# QN9090 register map
Vendor: nxp.com; File version: 1.0
CPU: CM4 r0p1, little endian, MPU, no FPU, VTOR, 3 interrupt priority bits
Registers are 32-bit, read-write, reset 0x0 unless marked. A register's access mark holds for its fields unless they carry their own. Offsets are from the block's base; [hi:lo] are bit positions; {n}, {i} and the like mark numbered series.

## GPIO — This is the description of component gpio It is General Purpose I/O with APB bus interface. More details will follow.
Base 0x40080000
{0x0+i} B[{i}] (i=0..21) 8-bit — Byte pin registers. Read 0: pin PIOn is LOW. Read 0xFF: pin PIOn is HIGH. Only 0 or 0xFF can be read. Write 0: clear output bit. Write any value 0x01 to 0xFF: set output bit. Reset values reflects the state of pin given by the relevant bit of PIN reset value
  [7:0] B
{0x1000+4i} W[{i}] (i=0..21) — Word pin registers Read 0: pin PIOn is LOW. Read 0xFFFFFFFF: pin PIOn is HIGH. Only 0 or 0xFFFF FFFF can be read. Write 0: clear output bit. Write any value 0x00000001 to 0xFFFFFFFF: set output bit. Reset values reflects the state of pin given by the relevant bit of PIN reset value
  [31:0] W
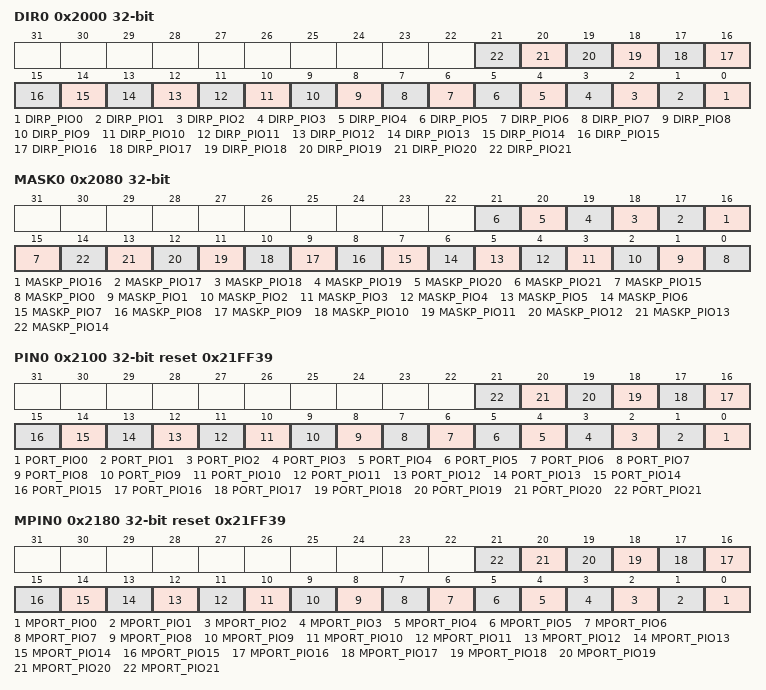
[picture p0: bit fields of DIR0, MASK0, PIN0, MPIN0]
0x2000 DIR0 — Direction register
  [n] DIRP_PIO{n} (n=0..21) — Selects pin direction for pin PIO{n} . 0 = input. 1 = output.
0x2080 MASK0 — Mask register
  [n] MASKP_PIO{n} (n=16..21) — Controls if PIO{n} is active in MPIN register. 0 = Mask bit is clear, the PIO will be active. 1 = Mask bit is set, the PIO will not be active.
  [15] MASKP_PIO15 — Controls if PIO150 is active in MPIN register. 0 = Mask bit is clear, the PIO will be active. 1 = Mask bit is set, the PIO will not be active.
  [n] MASKP_PIO{n} (n=0..14) — Controls if PIO{n} is active in MPIN register. 0 = Mask bit is clear, the PIO will be active. 1 = Mask bit is set, the PIO will not be active.
0x2100 PIN0 reset 0x21FF39 — Pin register
  [n] PORT_PIO{n} (n=0..21) — Reads pin states or loads output bits. 0 = Read: pin is low; write: clear output bit. 1 = Read: pin is high; write: set output bit.
0x2180 MPIN0 reset 0x21FF39 — Masked Pin register
  [n] MPORT_PIO{n} (n=0..21) — Masked pin register. 0 = Read: pin is LOW and/or the corresponding bit in the MASK register is 1; write: clear output bit if the corresponding bit in the MASK register is 0. 1 = Read: pin is HIGH and the corresponding bit in the MASK register is 0; write: set output bit if the corresponding bit in the MASK register is 0.
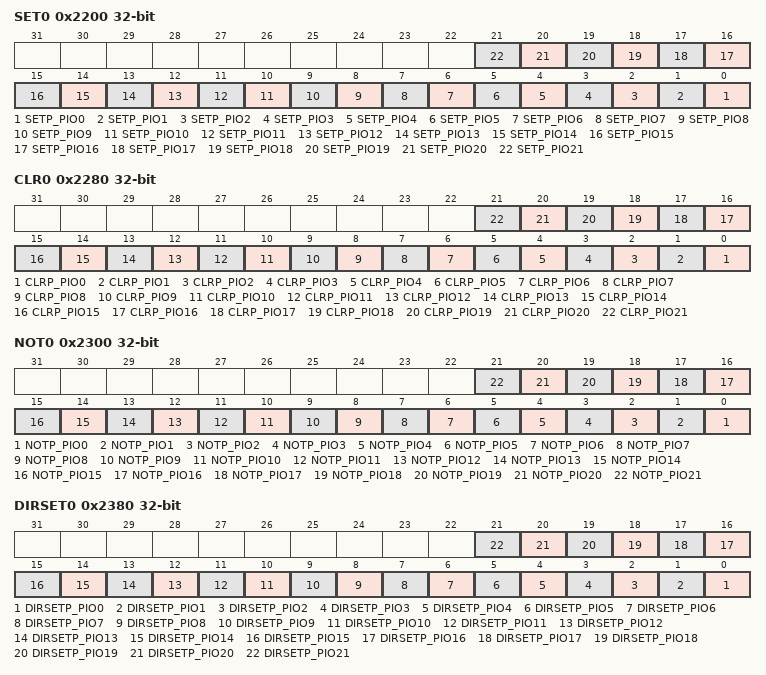
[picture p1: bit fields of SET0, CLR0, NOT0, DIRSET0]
0x2200 SET0 — Write: Set Pin register bits Read: output bits
  [n] SETP_PIO{n} (n=0..21) — Read or set output bits. 0 = Read: output bit: write: no operation. 1 = Read: output bit; write: set output bit.
0x2280 CLR0 reset not defined — Clear Pin register bits
  [n] CLRP_PIO{n} wo (n=0..21) — Clear output bits. 0 = No operation. 1 = Clear output bit.
0x2300 NOT0 reset not defined — Toggle Pin register bits
  [n] NOTP_PIO{n} wo (n=0..21) — Toggle output bits. 0 = no operation. 1 = Toggle output bit.
0x2380 DIRSET0 reset not defined — Set pin direction bits
  [n] DIRSETP_PIO{n} wo (n=0..21) — Set direction bits. 0 = no operation. 1 = Set direction bit.
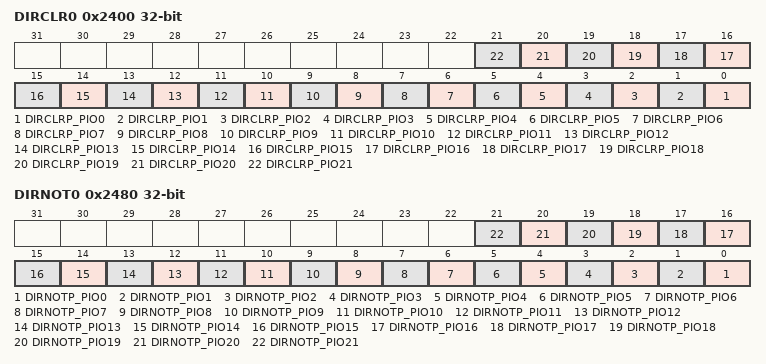
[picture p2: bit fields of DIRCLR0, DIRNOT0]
0x2400 DIRCLR0 reset not defined — Clear pin direction bits
  [n] DIRCLRP_PIO{n} wo (n=0..21) — Clear direction bits. 0 = no operation. 1 = Clear direction bit.
0x2480 DIRNOT0 reset not defined — Toggle pin direction bits
  [n] DIRNOTP_PIO{n} wo (n=0..21) — Toggle direction bits. 0 = no operation. 1 = Toggle direction bit.

## AES0 — AES
Base 0x40086000
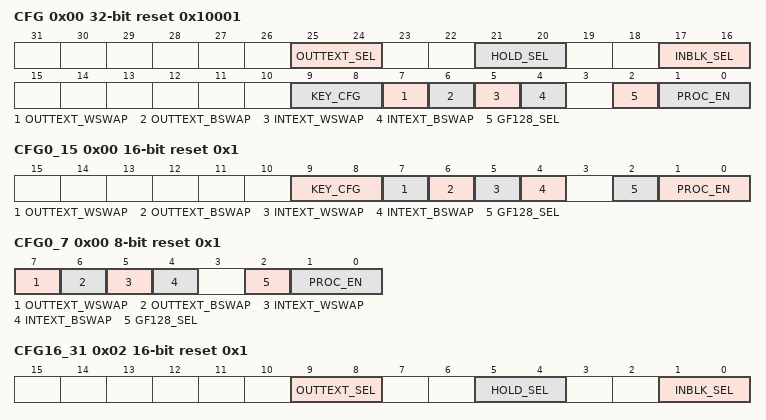
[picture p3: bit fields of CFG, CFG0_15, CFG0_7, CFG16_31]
0x00 CFG reset 0x10001 (CFG_CFG0_15_CFG0_7 view) — AES Configuration register
  [25:24] OUTTEXT_SEL — Output text source select.
  [21:20] HOLD_SEL — Holding register source select.
  [17:16] INBLK_SEL — Input block select.
  [9:8] KEY_CFG — Key Configuration.
  [7] OUTTEXT_WSWAP — Word swap output text.
  [6] OUTTEXT_BSWAP — Byte swap output text.
  [5] INTEXT_WSWAP — Word swap input text.
  [4] INTEXT_BSWAP — Byte swap input text.
  [2] GF128_SEL — GF128 hash selection.
  [1:0] PROC_EN — Process type enable.
0x00 CFG0_15 16-bit reset 0x1 (CFG_CFG0_15_CFG0_7 view) — AES Configuration register 0:15
  [9:8] KEY_CFG — Key Configuration.
  [7] OUTTEXT_WSWAP — Word swap output text.
  [6] OUTTEXT_BSWAP — Byte swap output text.
  [5] INTEXT_WSWAP — Word swap input text.
  [4] INTEXT_BSWAP — Byte swap input text.
  [2] GF128_SEL — GF128 hash selection.
  [1:0] PROC_EN — Process type enable.
0x00 CFG0_7 8-bit reset 0x1 (CFG_CFG0_15_CFG0_7 view) — AES Configuration register 0:7
  [7] OUTTEXT_WSWAP — Word swap output text.
  [6] OUTTEXT_BSWAP — Byte swap output text.
  [5] INTEXT_WSWAP — Word swap input text.
  [4] INTEXT_BSWAP — Byte swap input text.
  [2] GF128_SEL — GF128 hash selection.
  [1:0] PROC_EN — Process type enable.
0x01 CFG8_15 8-bit — AES Configuration register 8:15
  [1:0] KEY_CFG — Key Configuration.
0x02 CFG16_31 16-bit reset 0x1 — AES Configuration register 16:31
  [9:8] OUTTEXT_SEL — Output text source select.
  [5:4] HOLD_SEL — Holding register source select.
  [1:0] INBLK_SEL — Input block select.
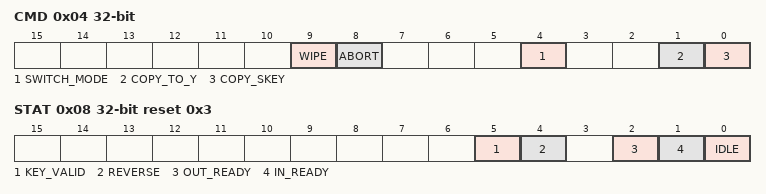
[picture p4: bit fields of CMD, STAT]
0x04 CMD (reset mask 0x312) — AES Command register
  [9] WIPE — When set this bit performs abort, clears KEY and GF128_Y registers and disables cipher.
  [8] ABORT — Aborts Encrypt/Decrypt and GF128 Hash operation.
  [4] SWITCH_MODE — When this bit is set the mode switches from forward mode (encryption) to reverse mode (decryption) or reverse mode to forward mode.
  [1] COPY_TO_Y — Copy output text to GF128Y.
  [0] COPY_SKEY wo — Copies Secret Key and Enables Cipher
0x08 STAT reset 0x3 — AES Status register
  [5] KEY_VALID
  [4] REVERSE — Reverse mode.
  [2] OUT_READY — Output text ready.
  [1] IN_READY — Input text ready.
  [0] IDLE — AES engine Idle.
0x0C CTR_INCR — Counter Increment
  [31:0] CTR_INCR — Increment value for HOLDING register when in counter modes.
{0x20+4i} KEY[{i}] (i=0..7) wo — Bits of the AES key
  [31:0] KEY — Contains the bits of the AES key.
{0x40+4i} INTEXT[{i}] (i=0..3) wo — Input text bits
  [31:0] INTEXT — Contains bits of the AES key.
{0x50+4i} HOLDING[{i}] (i=0..3) wo — Holding register bits
  [31:0] HOLDING — Contains the first word (bits 31:0) of the 128 bit Holding value.
{0x60+4i} OUTTEXT[{i}] (i=0..3) ro — Output text bits
  [31:0] OUTTEXT — Contains the bits of the 128 bit Output text data.
{0x70+4i} GF128_Y[{i}] (i=0..3) wo — Y bits input of GF128 hash
  [31:0] GF128_Y — Contains the bits of the Y input of GF128 hash.
{0x80+4i} GF128_Z[{i}] (i=0..3) ro — Result bits of GF128 hash
  [31:0] GF128_Z — Contains bits of the result of GF128 hash.
{0x90+4i} GCM_TAG[{i}] (i=0..3) ro — GCM Tag bits
  [31:0] GCM_TAG — Contains bits of the 128 bit GCM tag.

## FLEXCOMM0 — LPC5411x Flexcomm serial communication
Base 0x4008B000
Same registers: FLEXCOMM2 0x40003000, FLEXCOMM3 0x40004000, FLEXCOMM6 0x40005000, FLEXCOMM1 0x4008C000, FLEXCOMM4 0x4008D000, FLEXCOMM5 0x4008E000
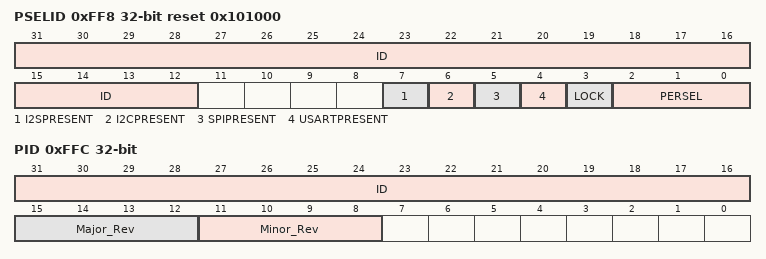
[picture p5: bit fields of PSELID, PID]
0xFF8 PSELID reset 0x101000 — Peripheral Select and Flexcomm ID register.
  [31:12] ID ro — Flexcomm ID.
  [7] I2SPRESENT ro — I 2S present indicator. This field is Read-only.
    0=NOT_PRESENT (This Flexcomm does not include the I2S function.); 1=PRESENT (This Flexcomm includes the I2S function.)
  [6] I2CPRESENT ro — I2C present indicator. This field is Read-only.
    0=NOT_PRESENT (This Flexcomm does not include the I2C function.); 1=PRESENT (This Flexcomm includes the I2C function.)
  [5] SPIPRESENT ro — SPI present indicator. This field is Read-only.
    0=NOT_PRESENT (This Flexcomm does not include the SPI function.); 1=PRESENT (This Flexcomm includes the SPI function.)
  [4] USARTPRESENT ro — USART present indicator. This field is Read-only.
    0=NOT_PRESENT (This Flexcomm does not include the USART function.); 1=PRESENT (This Flexcomm includes the USART function.)
  [3] LOCK — Lock the peripheral select. This field is writable by software.
    0=UNLOCKED (Peripheral select can be changed by software.); 1=LOCKED (Peripheral select is locked and cannot be changed until this Flexcomm or the entire device is reset.)
  [2:0] PERSEL — Peripheral Select. This field is writable by software.
    0=NO_PERIPH_SELECTED (No peripheral selected.); 1=USART (USART function selected.); 2=SPI (SPI function selected.); 3=I2C (I2C function selected.); 4=I2S_TRANSMIT (I2S transmit function selected.); 5=I2S_RECEIVE (I2S receive function selected.)
0xFFC PID — Peripheral identification register.
  [31:16] ID — Module identifier for the selected function.
  [15:12] Major_Rev ro — Major revision of module implementation.
  [11:8] Minor_Rev ro — Minor revision of module implementation.
